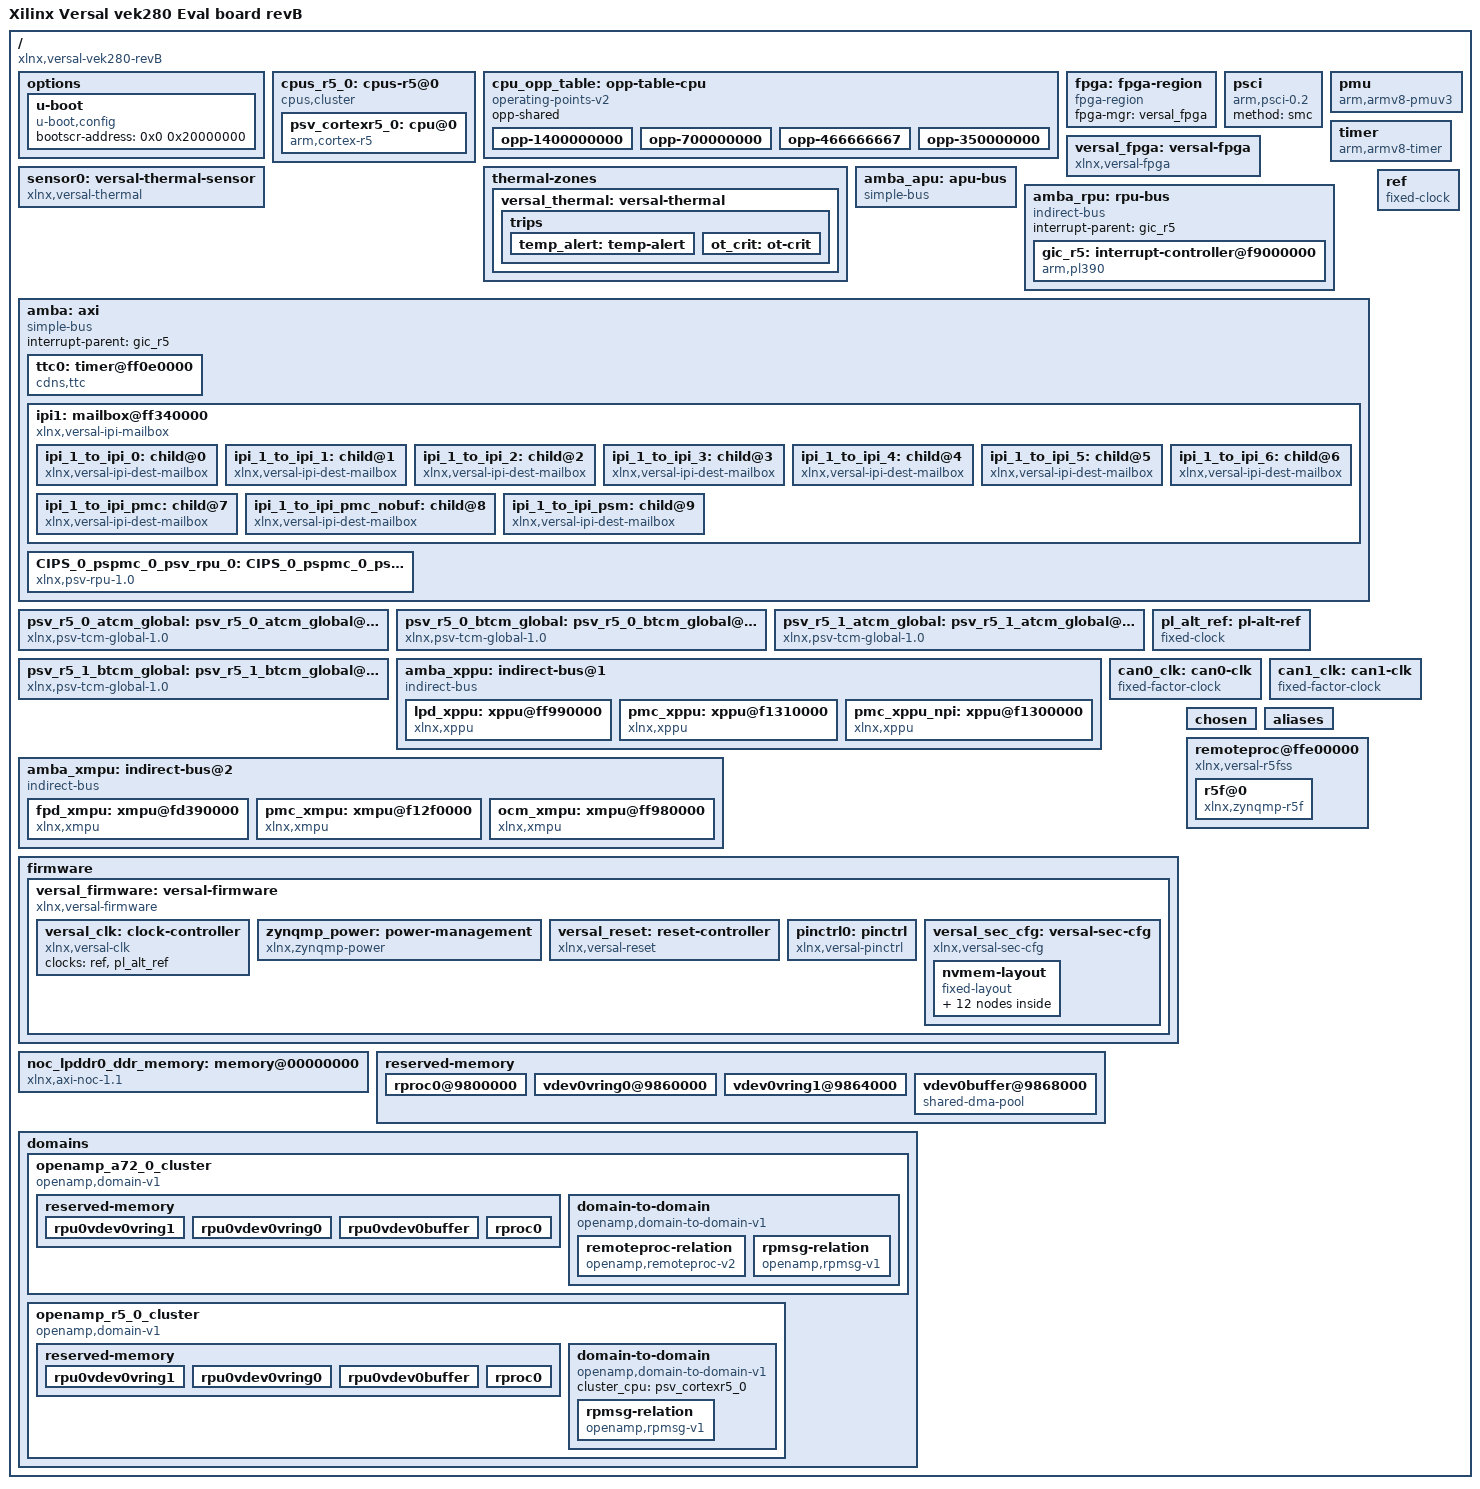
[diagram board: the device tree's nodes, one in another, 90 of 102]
/dts-v1/;
/ {
        compatible = "xlnx,versal-vek280-revB", "xlnx,versal-vek280", "xlnx,versal", "Xilinx Versal vek280 Eval board revB", "Xilinx Versal vek280 Eval board revB", "Xilinx Versal vek280 Eval board revB", "Xilinx Versal vek280 Eval board revB", "Xilinx Versal vek280 Eval board revB", "Xilinx Versal vek280 Eval board revB";
        #address-cells = <0x2>;
        #size-cells = <0x2>;
        model = "Xilinx Versal vek280 Eval board revB";
        board = "vek280";
        device_id = "xcve2802";
        slrcount = <0x1>;
        family = "Versal";
        speed_grade = "2MP";
        pruned-sdt = <0x1>;

        options {

                u-boot {
                        compatible = "u-boot,config";
                        bootscr-address = <0x0 0x20000000>;
                };
        };

        cpus_r5_0: cpus-r5@0 {
                phandle = <0xab>;
                #address-cells = <0x1>;
                #size-cells = <0x0>;
                compatible = "cpus,cluster";
                address-map = <0xf0000000 &amba 0xf0000000 0x10000000>,
                 <0xf9000000 &amba_rpu 0xf9000000 0x3000>,
                 <0x40000 &noc_lpddr0_ddr_memory 0x40000 0x7ffc0000>,
                 <0xff340000 &ipi1 0xff340000 0x10000>,
                 <0xf12f0000 &pmc_xmpu 0xf12f0000 0x10000>,
                 <0xf1300000 &pmc_xppu_npi 0xf1300000 0x10000>,
                 <0xf1310000 &pmc_xppu 0xf1310000 0x10000>,
                 <0xfd390000 &fpd_xmpu 0xfd390000 0x10000>,
                 <0xff0e0000 &ttc0 0xff0e0000 0x10000>,
                 <0xff980000 &ocm_xmpu 0xff980000 0x10000>,
                 <0xff990000 &lpd_xppu 0xff990000 0x10000>,
                 <0xff9a0000 &CIPS_0_pspmc_0_psv_rpu_0 0xff9a0000 0x10000>,
                 <0xf9000000 &gic_r5 0xf9000000 0x3000>;
                #ranges-address-cells = <0x1>;
                #ranges-size-cells = <0x1>;

                psv_cortexr5_0: cpu@0 {
                        phandle = <0xac>;
                        compatible = "arm,cortex-r5";
                        device_type = "cpu";
                        reg = <0x0>;
                        operating-points-v2 = <&cpu_opp_table>;
                        power-domains = <&versal_firmware 0x18110005>;
                        xlnx,is-cache-coherent = <0x0>;
                        xlnx,pss-ref-clk-freq = <0x1fca034>;
                        xlnx,ip-name = "psv_cortexr5";
                        access-val = <0xff>;
                        bus-handle = <0x1>;
                        xlnx,cpu-clk-freq-hz = <0x23c343db>;
                        cpu-frequency = <0x23c343db>;
                };
        };

        cpu_opp_table: opp-table-cpu {
                phandle = <0x7d>;
                compatible = "operating-points-v2";
                opp-shared;

                opp-1400000000 {
                        opp-hz = <0x0 0x53724e00>;
                        clock-latency-ns = <0x7a120>;
                        opp-microvolt = <0xf4240>;
                };

                opp-700000000 {
                        opp-hz = <0x0 0x29b92700>;
                        clock-latency-ns = <0x7a120>;
                        opp-microvolt = <0xf4240>;
                };

                opp-466666667 {
                        opp-hz = <0x0 0x1bd0c4ab>;
                        clock-latency-ns = <0x7a120>;
                        opp-microvolt = <0xf4240>;
                };

                opp-350000000 {
                        opp-hz = <0x0 0x14dc9380>;
                        clock-latency-ns = <0x7a120>;
                        opp-microvolt = <0xf4240>;
                };
        };

        fpga: fpga-region {
                phandle = <0xb0>;
                compatible = "fpga-region";
                fpga-mgr = <&versal_fpga>;
                #address-cells = <0x2>;
                #size-cells = <0x2>;
        };

        psci: psci {
                phandle = <0xb1>;
                compatible = "arm,psci-0.2";
                method = "smc";
        };

        pmu {
                compatible = "arm,armv8-pmuv3";
                interrupt-parent = <&gic_r5>;
                interrupts = <0x1 0x7 0x304>;
        };

        timer: timer {
                phandle = <0xb2>;
                compatible = "arm,armv8-timer";
                interrupt-parent = <&gic_r5>;
                interrupts = <0x1 0xd 0x4 0x1 0xe 0x4 0x1 0xb 0x4 0x1 0xa 0x4>;
        };

        versal_fpga: versal-fpga {
                phandle = <0x97>;
                compatible = "xlnx,versal-fpga";
        };

        sensor0: versal-thermal-sensor {
                phandle = <0x99>;
                compatible = "xlnx,versal-thermal";
                #thermal-sensor-cells = <0x0>;
                io-channel-names = "sysmon-temp-channel";
        };

        thermal-zones {

                versal_thermal: versal-thermal {
                        phandle = <0xb3>;
                        polling-delay-passive = <0xfa>;
                        polling-delay = <0x3e8>;
                        thermal-sensors = <0x99>;

                        trips {

                                temp_alert: temp-alert {
                                        phandle = <0xb4>;
                                        temperature = <0x11170>;
                                        hysteresis = <0x0>;
                                        type = "passive";
                                };

                                ot_crit: ot-crit {
                                        phandle = <0xb5>;
                                        temperature = <0x1e848>;
                                        hysteresis = <0x0>;
                                        type = "critical";
                                };
                        };
                };
        };

        amba_apu: apu-bus {
                phandle = <0x2>;
                compatible = "simple-bus";
                #address-cells = <0x2>;
                #size-cells = <0x2>;
                ranges;
                bootph-all;
        };

        amba_rpu: rpu-bus {
                phandle = <0x8a>;
                compatible = "indirect-bus";
                #address-cells = <0x2>;
                #size-cells = <0x2>;
                ranges;
                interrupt-parent = <&gic_r5>;
                bootph-all;

                gic_r5: interrupt-controller@f9000000 {
                        phandle = <0x8f>;
                        compatible = "arm,pl390";
                        #interrupt-cells = <0x3>;
                        interrupt-controller;
                        status = "okay";
                        reg = <0x0 0xf9000000 0x0 0x1000 0x0 0xf9001000 0x0 0x1000>;
                        xlnx,ip-name = "psv_rcpu_gic";
                        xlnx,name = "CIPS_0_pspmc_0_psv_rcpu_gic";
                };
        };

        amba: axi {
                phandle = <0x1>;
                compatible = "simple-bus";
                #address-cells = <0x2>;
                #size-cells = <0x2>;
                ranges;
                interrupt-parent = <&gic_r5>;
                bootph-all;

                ttc0: timer@ff0e0000 {
                        phandle = <0x64>;
                        compatible = "cdns,ttc";
                        status = "okay";
                        interrupts = <0x0 0x25 0x4 0x0 0x26 0x4 0x0 0x27 0x4>;
                        interrupt-parent = <&gic_r5>;
                        reg = <0x0 0xff0e0000 0x0 0x1000>;
                        timer-width = <0x20>;
                        clocks = <&versal_clk 0x27>;
                        power-domains = <&versal_firmware 0x18224024>;
                        xlnx,ttc-board-interface = "custom";
                        xlnx,ttc-clk2-freq-hz = <0x8f0d0f7>;
                        xlnx,ttc-clk1-clksrc = <0x0>;
                        xlnx,clock-freq = <0x8f0d0f7>;
                        xlnx,ttc-clk2-clksrc = <0x0>;
                        xlnx,ip-name = "psv_ttc";
                        xlnx,ttc-clk0-freq-hz = <0x8f0d0f7>;
                        xlnx,ttc-clk1-freq-hz = <0x8f0d0f7>;
                        xlnx,ttc-clk0-clksrc = <0x0>;
                        xlnx,name = "CIPS_0_pspmc_0_psv_ttc_0";
                };

                ipi1: mailbox@ff340000 {
                        phandle = <0x8b>;
                        status = "okay";
                        compatible = "xlnx,versal-ipi-mailbox";
                        interrupt-parent = <&gic_r5>;
                        interrupts = <0x0 0x1f 0x4>;
                        reg = <0x0 0xff340000 0x0 0x10000 0x0 0xff3f0600 0x0 0x200>;
                        xlnx,ipi-bitmask = <0x8>;
                        xlnx,ipi-id = <0x3>;
                        xlnx,ipi-buf-index = <0x3>;
                        #address-cells = <0x2>;
                        #size-cells = <0x2>;
                        ranges;
                        xlnx,cpu-name = "R5_0";
                        xlnx,buffer-base = <0xff3f0600>;
                        xlnx,buffer-index = <0x3>;
                        xlnx,ip-name = "psv_ipi";
                        xlnx,ipi-target-count = <0xa>;
                        reg-names = "ctrl", "msg";
                        xlnx,int-id = <0x3f>;
                        xlnx,bit-position = <0x3>;
                        xlnx,name = "CIPS_0_pspmc_0_psv_ipi_1";

                        ipi_1_to_ipi_0: child@0 {
                                phandle = <0xfa>;
                                compatible = "xlnx,versal-ipi-dest-mailbox";
                                xlnx,ipi-bitmask = <0x4>;
                                xlnx,cpu-name = "A72";
                                xlnx,ipi-rsp-msg-buf = <0xff3f06a0>;
                                #mbox-cells = <0x1>;
                                xlnx,ipi-id = <0x2>;
                                reg = <0x0 0xff330000 0x0 0x10000 0x0 0xff3f0400 0x0 0x200>;
                                xlnx,ipi-buf-index = <0x2>;
                                xlnx,ipi-req-msg-buf = <0xff3f0680>;
                                reg-names = "ctrl", "msg";
                        };

                        ipi_1_to_ipi_1: child@1 {
                                phandle = <0xfb>;
                                compatible = "xlnx,versal-ipi-dest-mailbox";
                                xlnx,ipi-bitmask = <0x8>;
                                xlnx,cpu-name = "R5_0";
                                xlnx,ipi-rsp-msg-buf = <0xff3f06e0>;
                                #mbox-cells = <0x1>;
                                xlnx,ipi-id = <0x3>;
                                reg = <0x0 0xff340000 0x0 0x10000 0x0 0xff3f0600 0x0 0x200>;
                                xlnx,ipi-buf-index = <0x3>;
                                xlnx,ipi-req-msg-buf = <0xff3f06c0>;
                                reg-names = "ctrl", "msg";
                        };

                        ipi_1_to_ipi_2: child@2 {
                                phandle = <0xfc>;
                                compatible = "xlnx,versal-ipi-dest-mailbox";
                                xlnx,ipi-bitmask = <0x10>;
                                xlnx,cpu-name = "R5_1";
                                xlnx,ipi-rsp-msg-buf = <0xff3f0720>;
                                #mbox-cells = <0x1>;
                                xlnx,ipi-id = <0x4>;
                                reg = <0x0 0xff350000 0x0 0x10000 0x0 0xff3f0800 0x0 0x200>;
                                xlnx,ipi-buf-index = <0x4>;
                                xlnx,ipi-req-msg-buf = <0xff3f0700>;
                                reg-names = "ctrl", "msg";
                        };

                        ipi_1_to_ipi_3: child@3 {
                                phandle = <0xfd>;
                                compatible = "xlnx,versal-ipi-dest-mailbox";
                                xlnx,ipi-bitmask = <0x20>;
                                xlnx,cpu-name = "A72";
                                xlnx,ipi-rsp-msg-buf = <0xff3f0760>;
                                #mbox-cells = <0x1>;
                                xlnx,ipi-id = <0x5>;
                                reg = <0x0 0xff360000 0x0 0x10000 0x0 0xff3f0a00 0x0 0x200>;
                                xlnx,ipi-buf-index = <0x5>;
                                xlnx,ipi-req-msg-buf = <0xff3f0740>;
                                reg-names = "ctrl", "msg";
                        };

                        ipi_1_to_ipi_4: child@4 {
                                phandle = <0xfe>;
                                compatible = "xlnx,versal-ipi-dest-mailbox";
                                xlnx,ipi-bitmask = <0x40>;
                                xlnx,cpu-name = "A72";
                                xlnx,ipi-rsp-msg-buf = <0xff3f07a0>;
                                #mbox-cells = <0x1>;
                                xlnx,ipi-id = <0x6>;
                                reg = <0x0 0xff370000 0x0 0x10000 0x0 0xff3f0c00 0x0 0x200>;
                                xlnx,ipi-buf-index = <0x6>;
                                xlnx,ipi-req-msg-buf = <0xff3f0780>;
                                reg-names = "ctrl", "msg";
                        };

                        ipi_1_to_ipi_5: child@5 {
                                phandle = <0xff>;
                                compatible = "xlnx,versal-ipi-dest-mailbox";
                                xlnx,ipi-bitmask = <0x80>;
                                xlnx,cpu-name = "A72";
                                xlnx,ipi-rsp-msg-buf = <0xff3f07e0>;
                                #mbox-cells = <0x1>;
                                xlnx,ipi-id = <0x7>;
                                reg = <0x0 0xff380000 0x0 0x10000 0x0 0xff3f0e00 0x0 0x200>;
                                xlnx,ipi-buf-index = <0x7>;
                                xlnx,ipi-req-msg-buf = <0xff3f07c0>;
                                reg-names = "ctrl", "msg";
                        };

                        ipi_1_to_ipi_6: child@6 {
                                phandle = <0x100>;
                                compatible = "xlnx,versal-ipi-dest-mailbox";
                                xlnx,ipi-bitmask = <0x200>;
                                xlnx,cpu-name = "A72";
                                #mbox-cells = <0x1>;
                                xlnx,ipi-id = <0x9>;
                                reg = <0x0 0xff3a0000 0x0 0x10000>;
                                xlnx,ipi-buf-index = <0xffff>;
                                reg-names = "ctrl";
                        };

                        ipi_1_to_ipi_pmc: child@7 {
                                phandle = <0x101>;
                                compatible = "xlnx,versal-ipi-dest-mailbox";
                                xlnx,ipi-bitmask = <0x2>;
                                xlnx,cpu-name = "PMC";
                                xlnx,ipi-rsp-msg-buf = <0xff3f0660>;
                                #mbox-cells = <0x1>;
                                xlnx,ipi-id = <0x1>;
                                reg = <0x0 0xff320000 0x0 0x10000 0x0 0xff3f0200 0x0 0x200>;
                                xlnx,ipi-buf-index = <0x1>;
                                xlnx,ipi-req-msg-buf = <0xff3f0640>;
                                reg-names = "ctrl", "msg";
                        };

                        ipi_1_to_ipi_pmc_nobuf: child@8 {
                                phandle = <0x102>;
                                compatible = "xlnx,versal-ipi-dest-mailbox";
                                xlnx,ipi-bitmask = <0x100>;
                                xlnx,cpu-name = "PMC";
                                #mbox-cells = <0x1>;
                                xlnx,ipi-id = <0x8>;
                                reg = <0x0 0xff390000 0x0 0x10000>;
                                xlnx,ipi-buf-index = <0xffff>;
                                reg-names = "ctrl";
                        };

                        ipi_1_to_ipi_psm: child@9 {
                                phandle = <0x103>;
                                compatible = "xlnx,versal-ipi-dest-mailbox";
                                xlnx,ipi-bitmask = <0x1>;
                                xlnx,cpu-name = "PSM";
                                xlnx,ipi-rsp-msg-buf = <0xff3f0620>;
                                #mbox-cells = <0x1>;
                                xlnx,ipi-id = <0x0>;
                                reg = <0x0 0xff310000 0x0 0x10000 0x0 0xff3f0000 0x0 0x200>;
                                xlnx,ipi-buf-index = <0x0>;
                                xlnx,ipi-req-msg-buf = <0xff3f0600>;
                                reg-names = "ctrl", "msg";
                        };
                };

                CIPS_0_pspmc_0_psv_rpu_0: CIPS_0_pspmc_0_psv_rpu_0@ff9a0000 {
                        phandle = <0x6d>;
                        compatible = "xlnx,psv-rpu-1.0";
                        status = "okay";
                        xlnx,ip-name = "psv_rpu";
                        reg = <0x0 0xff9a0000 0x0 0x10000>;
                        xlnx,name = "CIPS_0_pspmc_0_psv_rpu_0";
                };
        };

        psv_r5_0_atcm_global: psv_r5_0_atcm_global@ffe00000 {
                phandle = <0x79>;
                compatible = "xlnx,psv-tcm-global-1.0", "mmio-sram";
                power-domains = <&versal_firmware 0x1831800b>;
                reg = <0x0 0xffe00000 0x0 0x10000>;
                status = "okay";
                xlnx,ip-name = "psv_tcm_global";
                xlnx,is-hierarchy;
                xlnx,name = "CIPS_0_pspmc_0_psv_r5_0_atcm_global";
        };

        psv_r5_0_btcm_global: psv_r5_0_btcm_global@ffe20000 {
                phandle = <0x141>;
                compatible = "xlnx,psv-tcm-global-1.0", "mmio-sram";
                power-domains = <&versal_firmware 0x1831800c>;
                reg = <0x0 0xffe20000 0x0 0x10000>;
                status = "okay";
                xlnx,ip-name = "psv_tcm_global";
                xlnx,is-hierarchy;
                xlnx,name = "CIPS_0_pspmc_0_psv_r5_0_btcm_global";
        };

        psv_r5_1_atcm_global: psv_r5_1_atcm_global@ffe90000 {
                phandle = <0x7a>;
                compatible = "xlnx,psv-tcm-global-1.0", "mmio-sram";
                power-domains = <&versal_firmware 0x1831800d>;
                reg = <0x0 0xffe90000 0x0 0x10000>;
                status = "okay";
                xlnx,ip-name = "psv_tcm_global";
                xlnx,name = "CIPS_0_pspmc_0_psv_r5_1_atcm_global";
        };

        psv_r5_1_btcm_global: psv_r5_1_btcm_global@ffeb0000 {
                phandle = <0x7b>;
                compatible = "xlnx,psv-tcm-global-1.0", "mmio-sram";
                power-domains = <&versal_firmware 0x1831800e>;
                reg = <0x0 0xffeb0000 0x0 0x10000>;
                status = "okay";
                xlnx,ip-name = "psv_tcm_global";
                xlnx,name = "CIPS_0_pspmc_0_psv_r5_1_btcm_global";
        };

        amba_xppu: indirect-bus@1 {
                phandle = <0x142>;
                compatible = "indirect-bus";
                #address-cells = <0x2>;
                #size-cells = <0x2>;

                lpd_xppu: xppu@ff990000 {
                        phandle = <0x6c>;
                        compatible = "xlnx,xppu";
                        #firewall-cells = <0x0>;
                        reg = <0x0 0xff990000 0x0 0x2000>;
                        status = "okay";
                        xlnx,ip-name = "psv_lpd_xppu";
                        xlnx,name = "CIPS_0_pspmc_0_psv_lpd_xppu_0";
                };

                pmc_xppu: xppu@f1310000 {
                        phandle = <0x4a>;
                        compatible = "xlnx,xppu";
                        #firewall-cells = <0x0>;
                        reg = <0x0 0xf1310000 0x0 0x2000>;
                        status = "okay";
                        xlnx,ip-name = "psv_pmc_xppu";
                        xlnx,name = "CIPS_0_pspmc_0_psv_pmc_xppu_0";
                };

                pmc_xppu_npi: xppu@f1300000 {
                        phandle = <0x49>;
                        compatible = "xlnx,xppu";
                        #firewall-cells = <0x0>;
                        reg = <0x0 0xf1300000 0x0 0x2000>;
                        status = "okay";
                        xlnx,ip-name = "psv_pmc_xppu_npi";
                        xlnx,name = "CIPS_0_pspmc_0_psv_pmc_xppu_npi_0";
                };
        };

        amba_xmpu: indirect-bus@2 {
                phandle = <0x143>;
                compatible = "indirect-bus";
                #address-cells = <0x2>;
                #size-cells = <0x2>;

                fpd_xmpu: xmpu@fd390000 {
                        phandle = <0x53>;
                        compatible = "xlnx,xmpu";
                        #firewall-cells = <0x0>;
                        reg = <0x0 0xfd390000 0x0 0x1000>;
                        status = "okay";
                        xlnx,ip-name = "psv_fpd_slave_xmpu";
                        xlnx,name = "CIPS_0_pspmc_0_psv_fpd_slave_xmpu_0";
                };

                pmc_xmpu: xmpu@f12f0000 {
                        phandle = <0x48>;
                        compatible = "xlnx,xmpu";
                        #firewall-cells = <0x0>;
                        reg = <0x0 0xf12f0000 0x0 0x1000>;
                        status = "okay";
                        xlnx,ip-name = "psv_pmc_xmpu";
                        xlnx,name = "CIPS_0_pspmc_0_psv_pmc_xmpu_0";
                };

                ocm_xmpu: xmpu@ff980000 {
                        phandle = <0x6b>;
                        compatible = "xlnx,xmpu";
                        #firewall-cells = <0x0>;
                        reg = <0x0 0xff980000 0x0 0x1000>;
                        status = "okay";
                        xlnx,ip-name = "psv_ocm_xmpu";
                        xlnx,name = "CIPS_0_pspmc_0_psv_ocm_xmpu_0";
                };
        };

        pl_alt_ref: pl-alt-ref {
                phandle = <0xa1>;
                bootph-all;
                compatible = "fixed-clock";
                #clock-cells = <0x0>;
                clock-frequency = <0x1fca055>;
                clock-output-names = "pl_alt_ref_clk";
        };

        ref: ref {
                phandle = <0xa0>;
                bootph-all;
                compatible = "fixed-clock";
                #clock-cells = <0x0>;
                clock-frequency = <0x1fca034>;
                clock-output-names = "ref_clk";
        };

        can0_clk: can0-clk {
                phandle = <0x9a>;
                #clock-cells = <0x0>;
                compatible = "fixed-factor-clock";
                clocks = <&versal_clk 0x60>;
                clock-div = <0x2>;
                clock-mult = <0x1>;
                clock-output-names = "can0_clk";
        };

        can1_clk: can1-clk {
                phandle = <0x9b>;
                #clock-cells = <0x0>;
                compatible = "fixed-factor-clock";
                clocks = <&versal_clk 0x61>;
                clock-div = <0x2>;
                clock-mult = <0x1>;
                clock-output-names = "can1_clk";
        };

        firmware {

                versal_firmware: versal-firmware {
                        phandle = <0x7f>;
                        compatible = "xlnx,versal-firmware";
                        interrupt-parent = <&gic_r5>;
                        bootph-all;
                        method = "smc";
                        #power-domain-cells = <0x1>;

                        versal_clk: clock-controller {
                                phandle = <0x80>;
                                bootph-all;
                                #clock-cells = <0x1>;
                                compatible = "xlnx,versal-clk";
                                clocks = <&ref>,
                                 <&pl_alt_ref>;
                                clock-names = "ref", "pl_alt_ref";
                        };

                        zynqmp_power: power-management {
                                phandle = <0x148>;
                                compatible = "xlnx,zynqmp-power";
                        };

                        versal_reset: reset-controller {
                                phandle = <0x9d>;
                                compatible = "xlnx,versal-reset";
                                #reset-cells = <0x1>;
                        };

                        pinctrl0: pinctrl {
                                phandle = <0x149>;
                                compatible = "xlnx,versal-pinctrl";
                        };

                        versal_sec_cfg: versal-sec-cfg {
                                phandle = <0x14a>;
                                compatible = "xlnx,versal-sec-cfg";

                                nvmem-layout {
                                        compatible = "fixed-layout";
                                        #address-cells = <0x1>;
                                        #size-cells = <0x1>;

                                        bbram_zeroize: bbram-zeroize@4 {
                                                phandle = <0x14b>;
                                                reg = <0x4 0x4>;
                                        };

                                        bbram_key: bbram-key@10 {
                                                phandle = <0x14c>;
                                                reg = <0x10 0x20>;
                                        };

                                        bbram_usr: bbram-usr@30 {
                                                phandle = <0x14d>;
                                                reg = <0x30 0x4>;
                                        };

                                        bbram_lock: bbram-lock@48 {
                                                phandle = <0x14e>;
                                                reg = <0x48 0x4>;
                                        };

                                        user_key0: user-key@110 {
                                                phandle = <0x14f>;
                                                reg = <0x110 0x20>;
                                        };

                                        user_key1: user-key@130 {
                                                phandle = <0x150>;
                                                reg = <0x130 0x20>;
                                        };

                                        user_key2: user-key@150 {
                                                phandle = <0x151>;
                                                reg = <0x150 0x20>;
                                        };

                                        user_key3: user-key@170 {
                                                phandle = <0x152>;
                                                reg = <0x170 0x20>;
                                        };

                                        user_key4: user-key@190 {
                                                phandle = <0x153>;
                                                reg = <0x190 0x20>;
                                        };

                                        user_key5: user-key@1b0 {
                                                phandle = <0x154>;
                                                reg = <0x1b0 0x20>;
                                        };

                                        user_key6: user-key@1d0 {
                                                phandle = <0x155>;
                                                reg = <0x1d0 0x20>;
                                        };

                                        user_key7: user-key@1f0 {
                                                phandle = <0x156>;
                                                reg = <0x1f0 0x20>;
                                        };
                                };
                        };
                };
        };

        noc_lpddr0_ddr_memory: memory@00000000 {
                phandle = <0x5>;
                compatible = "xlnx,axi-noc-1.1";
                xlnx,ip-name = "axi_noc";
                device_type = "memory";
                reg = <0x0 0x40000 0x0 0x7ffc0000>;
                memory_type = "memory";
        };

        chosen {
                stdout-path = "serial0:115200";
                bootargs = "console=ttyAMA0 earlycon=pl011,mmio32,0xFF000000,115200n8";
        };

        aliases {
                serial0 = "/axi/serial@ff000000";
                serial1 = "/axi/coresight@f0800000";
                i2c0 = "/axi/i2c@ff020000";
                i2c1 = "/axi/i2c@ff030000";
                ethernet0 = "/axi/ethernet@ff0c0000";
                serial2 = "/dcc";
                mmc0 = "/axi/mmc@f1050000";
                spi0 = "/axi/spi@f1010000";
                usb0 = "/axi/usb@ff9d0000";
                rtc0 = "/axi/rtc@f12a0000";
                nvmem0 = "/axi/i2c@ff030000/eeprom@54";
        };

        __symbols__ {
                cpus_r5_0 = "/cpus-r5@0";
                psv_cortexr5_0 = "/cpus-r5@0/cpu@0";
                cpu_opp_table = "/opp-table-cpu";
                fpga = "/fpga-region";
                psci = "/psci";
                timer = "/timer";
                versal_fpga = "/versal-fpga";
                sensor0 = "/versal-thermal-sensor";
                versal_thermal = "/thermal-zones/versal-thermal";
                temp_alert = "/thermal-zones/versal-thermal/trips/temp-alert";
                ot_crit = "/thermal-zones/versal-thermal/trips/ot-crit";
                amba_apu = "/apu-bus";
                amba_rpu = "/rpu-bus";
                gic_r5 = "/rpu-bus/interrupt-controller@f9000000";
                amba = "/axi";
                imux = "/axi/interrupt-multiplex";
                ttc0 = "/axi/timer@ff0e0000";
                ipi1 = "/axi/mailbox@ff340000";
                ipi_1_to_ipi_0 = "/axi/mailbox@ff340000/child@0";
                ipi_1_to_ipi_1 = "/axi/mailbox@ff340000/child@1";
                ipi_1_to_ipi_2 = "/axi/mailbox@ff340000/child@2";
                ipi_1_to_ipi_3 = "/axi/mailbox@ff340000/child@3";
                ipi_1_to_ipi_4 = "/axi/mailbox@ff340000/child@4";
                ipi_1_to_ipi_5 = "/axi/mailbox@ff340000/child@5";
                ipi_1_to_ipi_6 = "/axi/mailbox@ff340000/child@6";
                ipi_1_to_ipi_pmc = "/axi/mailbox@ff340000/child@7";
                ipi_1_to_ipi_pmc_nobuf = "/axi/mailbox@ff340000/child@8";
                ipi_1_to_ipi_psm = "/axi/mailbox@ff340000/child@9";
                CIPS_0_pspmc_0_psv_rpu_0 = "/axi/CIPS_0_pspmc_0_psv_rpu_0@ff9a0000";
                psv_r5_0_atcm_global = "/psv_r5_0_atcm_global@ffe00000";
                psv_r5_0_btcm_global = "/psv_r5_0_btcm_global@ffe20000";
                psv_r5_1_atcm_global = "/psv_r5_1_atcm_global@ffe90000";
                psv_r5_1_btcm_global = "/psv_r5_1_btcm_global@ffeb0000";
                amba_xppu = "/indirect-bus@1";
                lpd_xppu = "/indirect-bus@1/xppu@ff990000";
                pmc_xppu = "/indirect-bus@1/xppu@f1310000";
                pmc_xppu_npi = "/indirect-bus@1/xppu@f1300000";
                amba_xmpu = "/indirect-bus@2";
                fpd_xmpu = "/indirect-bus@2/xmpu@fd390000";
                pmc_xmpu = "/indirect-bus@2/xmpu@f12f0000";
                ocm_xmpu = "/indirect-bus@2/xmpu@ff980000";
                pl_alt_ref = "/pl-alt-ref";
                ref = "/ref";
                can0_clk = "/can0-clk";
                can1_clk = "/can1-clk";
                versal_firmware = "/firmware/versal-firmware";
                versal_clk = "/firmware/versal-firmware/clock-controller";
                zynqmp_power = "/firmware/versal-firmware/power-management";
                versal_reset = "/firmware/versal-firmware/reset-controller";
                pinctrl0 = "/firmware/versal-firmware/pinctrl";
                versal_sec_cfg = "/firmware/versal-firmware/versal-sec-cfg";
                bbram_zeroize = "/firmware/versal-firmware/versal-sec-cfg/nvmem-layout/bbram-zeroize@4";
                bbram_key = "/firmware/versal-firmware/versal-sec-cfg/nvmem-layout/bbram-key@10";
                bbram_usr = "/firmware/versal-firmware/versal-sec-cfg/nvmem-layout/bbram-usr@30";
                bbram_lock = "/firmware/versal-firmware/versal-sec-cfg/nvmem-layout/bbram-lock@48";
                user_key0 = "/firmware/versal-firmware/versal-sec-cfg/nvmem-layout/user-key@110";
                user_key1 = "/firmware/versal-firmware/versal-sec-cfg/nvmem-layout/user-key@130";
                user_key2 = "/firmware/versal-firmware/versal-sec-cfg/nvmem-layout/user-key@150";
                user_key3 = "/firmware/versal-firmware/versal-sec-cfg/nvmem-layout/user-key@170";
                user_key4 = "/firmware/versal-firmware/versal-sec-cfg/nvmem-layout/user-key@190";
                user_key5 = "/firmware/versal-firmware/versal-sec-cfg/nvmem-layout/user-key@1b0";
                user_key6 = "/firmware/versal-firmware/versal-sec-cfg/nvmem-layout/user-key@1d0";
                user_key7 = "/firmware/versal-firmware/versal-sec-cfg/nvmem-layout/user-key@1f0";
                noc_lpddr0_ddr_memory = "/memory@00000000";
        };

        reserved-memory {
                ranges = <0x1>;

                rproc0@9800000 {
                        no-map;
                        size = <0x60000>;
                        start = <0x9800000>;
                        reg = <0x0 0x9800000 0x0 0x60000>;
                        phandle = <0x165>;
                };

                vdev0vring0@9860000 {
                        phandle = <0x163>;
                        no-map;
                        size = <0x4000>;
                        start = <0x9860000>;
                        reg = <0x0 0x9860000 0x0 0x4000>;
                };

                vdev0vring1@9864000 {
                        phandle = <0x162>;
                        no-map;
                        size = <0x4000>;
                        start = <0x9864000>;
                        reg = <0x0 0x9864000 0x0 0x4000>;
                };

                vdev0buffer@9868000 {
                        phandle = <0x164>;
                        no-map;
                        size = <0x100000>;
                        start = <0x9868000>;
                        reg = <0x0 0x9868000 0x0 0x100000>;
                        compatible = "shared-dma-pool";
                };
        };

        domains {

                openamp_a72_0_cluster {
                        phandle = <0x15e>;
                        compatible = "openamp,domain-v1";
                        os,type = "linux";
                        access = <&cpus_r5_0 0x0>,
                         <&ipi1 0x0>,
                         <&psv_r5_0_atcm_global 0x0>,
                         <&psv_r5_0_btcm_global 0x0>;
                        access-json = "[{\"dev\": \"cpus_r5_0\", \"flags\": 0}, {\"dev\": \"ipi1\", \"flags\": 0}, {\"dev\": \"ipi3\", \"flags\": 0}, {\"dev\": \"psv_r5_0_atcm_global@ffe00000\", \"flags\": {}}, {\"dev\": \"psv_r5_0_btcm_global@ffe20000\", \"flags\": 0}, {\"dev\": \"amba_pl\"}, {\"dev\": \"ethernet@ff0d0000\"}, {\"dev\": \"spi@f1030000\"}, {\"dev\": \"mmc@f1040000\"}]";

                        reserved-memory {
                                ranges = <0x1>;
                                #size-cells = <0x2>;
                                #address-cells = <0x2>;

                                rpu0vdev0vring1 {
                                        phandle = <0x15c>;
                                        start = <0x9864000>;
                                        size = <0x4000>;
                                        no-map;
                                };

                                rpu0vdev0vring0 {
                                        phandle = <0x15b>;
                                        start = <0x9860000>;
                                        size = <0x4000>;
                                        no-map;
                                };

                                rpu0vdev0buffer {
                                        phandle = <0x15d>;
                                        start = <0x9868000>;
                                        size = <0x100000>;
                                        no-map;
                                };

                                rproc0 {
                                        phandle = <0x15a>;
                                        start = <0x9800000>;
                                        size = <0x60000>;
                                        no-map;
                                };
                        };

                        domain-to-domain {
                                compatible = "openamp,domain-to-domain-v1";

                                remoteproc-relation {
                                        compatible = "openamp,remoteproc-v2";
                                        remote = <0x159>;
                                        elfload;
                                        elfload0 = <0x79 0x141 0x15a>;
                                };

                                rpmsg-relation {
                                        compatible = "openamp,rpmsg-v1";
                                        openamp-xlnx-native = <0x0 0x0>;
                                        remote = <0x159>;
                                        mbox = <0xa>;
                                        carveouts = <0x15b 0x15c 0x15d>;
                                };
                        };
                };

                openamp_r5_0_cluster {
                        phandle = <0x159>;
                        compatible = "openamp,domain-v1";
                        cpus = <&cpus_r5_0 0x1 0x0>;
                        os,type = "freertos";
                        access = <&psv_r5_0_atcm_global 0x0>,
                         <&psv_r5_0_btcm_global 0x0>,
                         <&ipi1 0x0>,
                         <&noc_lpddr0_ddr_memory 0x0>,
                         <&noc_lpddr0_ddr_memory 0x0>,
                         <&ttc0 0x0>,
                         <&CIPS_0_pspmc_0_psv_rpu_0 0x0>;
                        cpu_config_str = "split";
                        core_num = "0";
                        access-json = "[{\"dev\": \"psv_r5_0_atcm_global@ffe00000\", \"flags\": 0}, {\"dev\": \"psv_r5_0_btcm_global@ffe20000\", \"flags\": 0}, {\"dev\": \"ipi1\", \"flags\": 0}, {\"dev\": \"ipi3\", \"flags\": 0}, {\"dev\": \"noc_lpddr0_ddr_memory\", \"flags\": 0}, {\"dev\": \"memory@00000000\", \"flags\": 0}, {\"dev\": \"timer@ff0e0000\", \"flags\": 0}, {\"dev\": \"ps_wizard_0_pmcps_0_psv_rpu_0@ff9a0000\", \"flags\": 0}, {\"dev\": \"CIPS_0_pspmc_0_psv_rpu_0@ff9a0000\", \"flags\": 0}]";

                        reserved-memory {
                                ranges = <0x1>;

                                rpu0vdev0vring1 {
                                        phandle = <0x160>;
                                        start = <0x9864000>;
                                        size = <0x4000>;
                                        no-map;
                                };

                                rpu0vdev0vring0 {
                                        phandle = <0x15f>;
                                        start = <0x9860000>;
                                        size = <0x4000>;
                                        no-map;
                                };

                                rpu0vdev0buffer {
                                        phandle = <0x161>;
                                        start = <0x9868000>;
                                        size = <0x100000>;
                                        no-map;
                                };

                                rproc0 {
                                        start = <0x9800000>;
                                        size = <0x60000>;
                                        no-map;
                                };
                        };

                        domain-to-domain {
                                compatible = "openamp,domain-to-domain-v1";
                                cluster_cpu = "psv_cortexr5_0";

                                rpmsg-relation {
                                        compatible = "openamp,rpmsg-v1";
                                        host = <0x15e>;
                                        mbox = <0x8b>;
                                        carveouts = <0x15f 0x160 0x161>;
                                };
                        };
                };
        };

        remoteproc@ffe00000 {
                compatible = "xlnx,versal-r5fss";
                xlnx,cluster-mode = <0x0>;
                xlnx,tcm-mode = <0x0>;
                #address-cells = <0x2>;
                #size-cells = <0x2>;
                ranges = <0x0 0x0 0x0 0xffe00000 0x0 0x10000 0x0 0x20000 0x0 0xffe20000 0x0 0x10000 0x1 0x0 0x0 0xffe90000 0x0 0x10000 0x1 0x20000 0x0 0xffeb0000 0x0 0x10000>;

                r5f@0 {
                        compatible = "xlnx,zynqmp-r5f";
                        reg-names = "atcm0", "btcm0";
                        reg = <0x0 0x0 0x0 0x10000 0x0 0x20000 0x0 0x10000>;
                        memory-region = <0x165 0x164 0x163 0x162>;
                        power-domains = <&versal_firmware 0x18110005>,
                         <&versal_firmware 0x1831800b>,
                         <&versal_firmware 0x1831800c>;
                        mboxes = <0xfd 0x0 0xfd 0x1>;
                        mbox-names = "tx", "rx";
                };
        };
};
